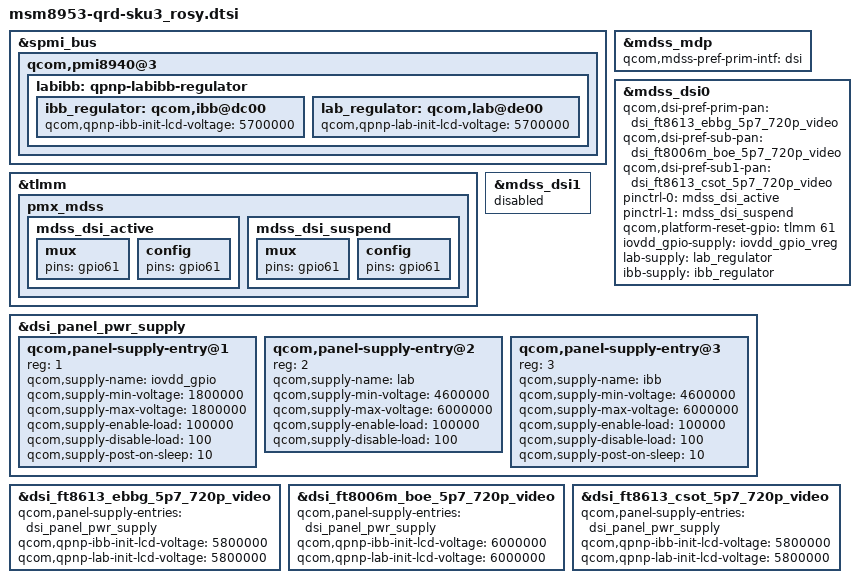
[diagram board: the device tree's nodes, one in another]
#include "dsi-panel-ft8613-ebbg-5p7-720p-video.dtsi"
#include "dsi-panel-ft8006m-boe-5p7-720p-video.dtsi"
#include "dsi-panel-ft8613-csot-5p7-720p-video.dtsi"

&spmi_bus {
	qcom,pmi8940@3 {
		labibb: qpnp-labibb-regulator {
			ibb_regulator: qcom,ibb@dc00 {
				/delete-property/ qcom,qpnp-ibb-use-default-voltage;
				qcom,qpnp-ibb-init-lcd-voltage = <5700000>;
			};

			lab_regulator: qcom,lab@de00 {
			//	/delete-property/ qcom,qpnp-ibb-use-default-voltage;
			//	qcom,qpnp-ibb-init-lcd-voltage = <5700000>;
				/delete-property/ qcom,qpnp-lab-use-default-voltage;
				qcom,qpnp-lab-init-lcd-voltage = <5700000>;
			};
		};
	};
};

&tlmm {
	pmx_mdss {
		mdss_dsi_active: mdss_dsi_active {
			mux {
				pins = "gpio61";
			};

			config {
				pins = "gpio61";
			};
		};

		mdss_dsi_suspend: mdss_dsi_suspend {
			mux {
				pins = "gpio61";
			};

			config {
				pins = "gpio61";
			};
		};
	};
};

&mdss_mdp {
	qcom,mdss-pref-prim-intf = "dsi";
};

&mdss_dsi0 {
	qcom,dsi-pref-prim-pan = <&dsi_ft8613_ebbg_5p7_720p_video>;
	qcom,dsi-pref-sub-pan = <&dsi_ft8006m_boe_5p7_720p_video>;
	qcom,dsi-pref-sub1-pan = <&dsi_ft8613_csot_5p7_720p_video>;
	pinctrl-names = "mdss_default", "mdss_sleep";
	pinctrl-0 = <&mdss_dsi_active>;
	pinctrl-1 = <&mdss_dsi_suspend>;
	qcom,platform-reset-gpio = <&tlmm 61 0>;
	iovdd_gpio-supply = <&iovdd_gpio_vreg>;
	lab-supply = <&lab_regulator>;
	ibb-supply = <&ibb_regulator>;
};

&mdss_dsi1 {
	status = "disabled";
};

&dsi_panel_pwr_supply {
	qcom,panel-supply-entry@1 {
		reg = <1>;
		qcom,supply-name = "iovdd_gpio";
		qcom,supply-min-voltage = <1800000>;
		qcom,supply-max-voltage = <1800000>;
		qcom,supply-enable-load = <100000>;
		qcom,supply-disable-load = <100>;
		qcom,supply-post-on-sleep = <10>;
	};

	qcom,panel-supply-entry@2 {
		reg = <2>;
		qcom,supply-name = "lab";
		qcom,supply-min-voltage = <4600000>;
		qcom,supply-max-voltage = <6000000>;
		qcom,supply-enable-load = <100000>;
		qcom,supply-disable-load = <100>;
	};

	qcom,panel-supply-entry@3 {
		reg = <3>;
		qcom,supply-name = "ibb";
		qcom,supply-min-voltage = <4600000>;
		qcom,supply-max-voltage = <6000000>;
		qcom,supply-enable-load = <100000>;
		qcom,supply-disable-load = <100>;
		qcom,supply-post-on-sleep = <10>;
	};
};

&dsi_ft8613_ebbg_5p7_720p_video {
	qcom,panel-supply-entries = <&dsi_panel_pwr_supply>;
	qcom,qpnp-ibb-init-lcd-voltage = <5800000>;
	qcom,qpnp-lab-init-lcd-voltage = <5800000>;
};

&dsi_ft8006m_boe_5p7_720p_video {
	qcom,panel-supply-entries = <&dsi_panel_pwr_supply>;
	qcom,qpnp-ibb-init-lcd-voltage = <6000000>;
	qcom,qpnp-lab-init-lcd-voltage = <6000000>;
};

&dsi_ft8613_csot_5p7_720p_video {
	qcom,panel-supply-entries = <&dsi_panel_pwr_supply>;
	qcom,qpnp-ibb-init-lcd-voltage = <5800000>;
	qcom,qpnp-lab-init-lcd-voltage = <5800000>;
};
